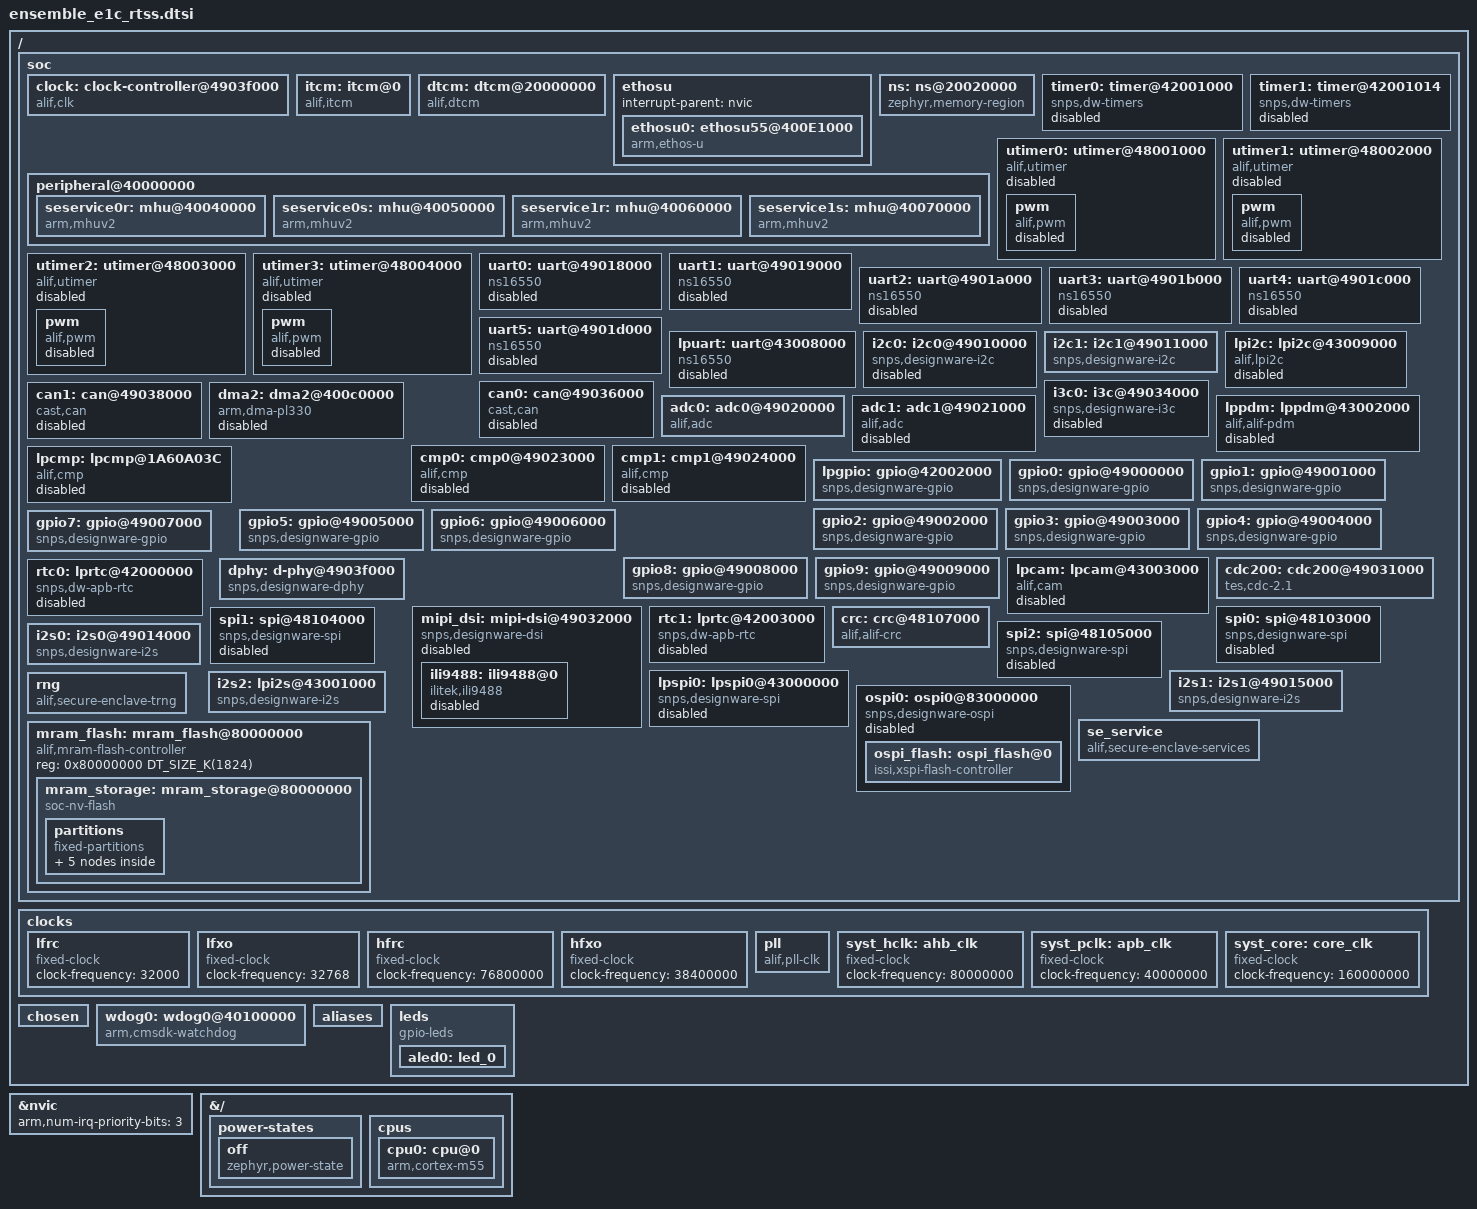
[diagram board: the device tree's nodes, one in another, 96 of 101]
/* Copyright (c) 2024 Alif Semiconductor
 *
 * SPDX-License-Identifier: Apache-2.0
 */
#include <arm/armv8.1-m.dtsi>
#include <zephyr/dt-bindings/timer/alif_utimer.h>
#include <zephyr/dt-bindings/pwm/pwm.h>
#include <zephyr/dt-bindings/clock/alif_balletto_clocks.h>
#include <zephyr/dt-bindings/mipi_dsi/mipi_dsi.h>
#include <zephyr/dt-bindings/display/ili9xxx.h>
#include <zephyr/dt-bindings/gpio/gpio.h>
#include <mem.h>
/ {
	soc {
		clock: clock-controller@4903f000 {
			compatible = "alif,clk";
			reg =  <0x4903F000 0xB0
				0x4902F000 0xBC
				0x1A604000 0x44
				0x1A609000 0x14
				0x43007000 0x2C>;
			reg-names = "master_clkctrl",
				     "slave_clkctrl",
				     "aon_clkctrl",
				     "vbat_clkctrl",
				     "m55he_clkctrl";
			#clock-cells = <1>;
			status = "okay";
		};
		itcm: itcm@0 {
			compatible = "alif,itcm", "zephyr,memory-region";
			reg = <0x0 DT_SIZE_K(512)>;
			itcm_global_base = <0x58000000>;
			zephyr,memory-region = "ITCM";
		};

		dtcm: dtcm@20000000 {
			compatible = "alif,dtcm", "zephyr,memory-region";
			dtcm_global_base = <0x58800000>;
			reg = <0x20000000 DT_SIZE_K(1536)>;
			zephyr,memory-region = "DTCM";
		};

		ethosu {
			#address-cells = <1>;
			#size-cells = <0>;
			interrupt-parent = <&nvic>;
			ethosu0: ethosu55@400E1000 {
				compatible = "arm,ethos-u";
				reg = <0x400E1000>;
				interrupts = <55 3>;
				secure-enable;
				privilege-enable;
				status = "okay";
			};
		};

		ns: ns@20020000 {
			compatible = "zephyr,memory-region", "mmio-region";
			reg = <0x20020000 DT_SIZE_K(512)>;
			zephyr,memory-region = "NS";
		};

		peripheral@40000000 {
			#address-cells = < 0x1 >;
			#size-cells = < 0x1 >;
			ranges = < 0x0 0x40000000 0x2000000 >;

			seservice0r: mhu@40040000 {
				compatible = "arm,mhuv2";
				reg = < 0x40040000 0x1000 >;
				interrupts = < 37 3 >;
				interrupt-names = "rx";
			};
			seservice0s: mhu@40050000 {
				compatible = "arm,mhuv2";
				reg = < 0x40050000 0x1000 >;
				interrupts = < 38 3 >;
				interrupt-names = "tx";
			};
			seservice1r: mhu@40060000 {
				compatible = "arm,mhuv2";
				reg = < 0x40060000 0x1000 >;
				interrupts = < 39 3 >;
				interrupt-names = "rx";
			};
			seservice1s: mhu@40070000 {
				compatible = "arm,mhuv2";
				reg = < 0x40070000 0x1000 >;
				interrupts = < 40 3 >;
				interrupt-names = "tx";
			};
		};

		timer0: timer@42001000 {
			compatible = "snps,dw-timers";
			reg = <0x42001000 0x14>;
			interrupts = < 60 3 >;
			clocks = <&clock ALIF_LPTIMER0_S32K_CLK>;
			status = "disabled";
		};

		timer1: timer@42001014 {
			compatible = "snps,dw-timers";
			reg = <0x42001014 0x14>;
			interrupts = < 61 3 >;
			clocks = <&clock ALIF_LPTIMER1_S32K_CLK>;
			status = "disabled";
		};

		utimer0: utimer@48001000 {
			compatible = "alif,utimer";
			reg = <0x48001000 0x1000 0x48000000 0x24>;
			reg-names = "timer", "global";
			timer-id = <0>;
			clock-frequency = <160000000>;
			counter-direction = < ALIF_UTIMER_COUNTER_DIRECTION_UP >;
			driver-enable = < ALIF_UTIMER_DRIVER_A_OUTPUT_ENABLE >;
			status = "disabled";

			pwm {
				compatible = "alif,pwm";
				#pwm-cells = <3>;
				status = "disabled";
			};
		};

		utimer1: utimer@48002000 {
			compatible = "alif,utimer";
			reg = <0x48002000 0x1000 0x48000000 0x24>;
			reg-names = "timer", "global";
			timer-id = <1>;
			clock-frequency = <160000000>;
			counter-direction = < ALIF_UTIMER_COUNTER_DIRECTION_UP >;
			driver-enable = < ALIF_UTIMER_DRIVER_A_OUTPUT_ENABLE >;
			status = "disabled";

			pwm {
				compatible = "alif,pwm";
				#pwm-cells = <3>;
				status = "disabled";
			};
		};

		utimer2: utimer@48003000 {
			compatible = "alif,utimer";
			reg = <0x48003000 0x1000 0x48000000 0x24>;
			reg-names = "timer", "global";
			timer-id = <2>;
			clock-frequency = <160000000>;
			counter-direction = < ALIF_UTIMER_COUNTER_DIRECTION_UP >;
			driver-enable = < ALIF_UTIMER_DRIVER_A_OUTPUT_ENABLE >;
			status = "disabled";

			pwm {
				compatible = "alif,pwm";
				#pwm-cells = <3>;
				status = "disabled";
			};
		};

		utimer3: utimer@48004000 {
			compatible = "alif,utimer";
			reg = <0x48004000 0x1000 0x48000000 0x24>;
			reg-names = "timer", "global";
			timer-id = <3>;
			clock-frequency = <160000000>;
			counter-direction = < ALIF_UTIMER_COUNTER_DIRECTION_UP >;
			driver-enable = < ALIF_UTIMER_DRIVER_A_OUTPUT_ENABLE >;
			status = "disabled";

			pwm {
				compatible = "alif,pwm";
				#pwm-cells = <3>;
				status = "disabled";
			};
		};

		uart0: uart@49018000 {
			compatible = "ns16550";
			reg = <0x49018000 0x100>;
			/* SYST_PCLK (APB bus) 40MHz baud clock */
			clock-frequency = <40000000>;
			interrupts = <124 3>;
			reg-shift = <2>;
			current-speed = <115200>;
			pinctrl-0 = < &pinctrl_uart0 >;
			pinctrl-names = "default";
			fifo-size = <32>;
			status = "disabled";
		};

		uart1: uart@49019000 {
			compatible = "ns16550";
			reg = <0x49019000 0x100>;
			/* SYST_PCLK (APB bus) 40MHz baud clock */
			clock-frequency = <40000000>;
			interrupts = <125 3>;
			reg-shift = <2>;
			current-speed = <115200>;
			pinctrl-0 = < &pinctrl_uart1 >;
			pinctrl-names = "default";
			fifo-size = <32>;
			status = "disabled";
		};

		uart2: uart@4901a000 {
			compatible = "ns16550";
			reg = <0x4901a000 0x100>;
			/* SYST_PCLK (APB bus) 40MHz baud clock */
			clock-frequency = <40000000>;
			interrupts = <126 3>;
			reg-shift = <2>;
			current-speed = <115200>;
			pinctrl-0 = < &pinctrl_uart2 >;
			pinctrl-names = "default";
			fifo-size = <32>;
			status = "disabled";
		};

		uart3: uart@4901b000 {
			compatible = "ns16550";
			reg = <0x4901b000 0x100>;
			/* SYST_PCLK (APB bus) 40MHz baud clock */
			clock-frequency = <40000000>;
			interrupts = <127 3>;
			reg-shift = <2>;
			current-speed = <115200>;
			pinctrl-0 = < &pinctrl_uart3 >;
			pinctrl-names = "default";
			fifo-size = <32>;
			status = "disabled";
		};

		uart4: uart@4901c000 {
			compatible = "ns16550";
			reg = <0x4901c000 0x100>;
			/* SYST_PCLK (APB bus) 40MHz baud clock */
			clock-frequency = <40000000>;
			interrupts = <128 3>;
			reg-shift = <2>;
			current-speed = <115200>;
			pinctrl-0 = < &pinctrl_uart4 >;
			pinctrl-names = "default";
			fifo-size = <32>;
			status = "disabled";
		};

		uart5: uart@4901d000 {
			compatible = "ns16550";
			reg = <0x4901d000 0x100>;
			/* SYST_PCLK (APB bus) 40MHz baud clock */
			clock-frequency = <40000000>;
			interrupts = <129 3>;
			reg-shift = <2>;
			current-speed = <115200>;
			pinctrl-0 = < &pinctrl_uart5 >;
			pinctrl-names = "default";
			fifo-size = <32>;
			status = "disabled";
		};

		lpuart: uart@43008000 {
			compatible = "ns16550";
			reg = <0x43008000 0x100>;
			/* RTSS_HE_CLK 160MHz baud clock */
			clock-frequency = <160000000>;
			interrupts = <45 3>;
			reg-shift = <2>;
			current-speed = <115200>;
			pinctrl-0 = < &pinctrl_lpuart >;
			pinctrl-names = "default";
			fifo-size = <32>;
			status = "disabled";
		};

		i2c0: i2c0@49010000 {
			compatible = "snps,designware-i2c";
			clock-frequency = <100000>;
			#address-cells = <1>;
			#size-cells = <0>;
			reg = <0x49010000 0x1000>;
			pinctrl-0 = < &pinctrl_i2c0 >;
			pinctrl-names = "default";
			interrupt-parent = <&nvic>;
			interrupts = <132 3>;
			status = "disabled";
		};

		i2c1: i2c1@49011000 {
			compatible = "snps,designware-i2c";
			clock-frequency = <100000>;
			#address-cells = <1>;
			#size-cells = <0>;
			reg = <0x49011000 0x1000>;
			pinctrl-0 = < &pinctrl_i2c1 >;
			pinctrl-names = "default";
			interrupt-parent = <&nvic>;
			interrupts = <133 3>;
			status = "okay";
		};

		lpi2c: lpi2c@43009000 {
			compatible = "alif,lpi2c";
			#address-cells = <1>;
			#size-cells = <0>;
			pinctrl-names = "default";
			pinctrl-0 = <&pinctrl_lpi2c>;
			reg = <0x43009000 0x100>;
			interrupts = <47 3>;
			status = "disabled";
		};

		i3c0: i3c@49034000 {
			compatible      = "snps,designware-i3c";
			#address-cells  = <3>;
			#size-cells     = <0>;
			reg             = <0x49034000 0x1000>;
			interrupt-parent= <&nvic>;
			interrupts      = <136 3>;
			clocks          = <&clock ALIF_I3C_CLK>;
			pinctrl-0       = <&pinctrl_i3c0>;
			pinctrl-names   = "default";
			i3c-scl-hz      = <12500000>;
			i2c-scl-hz      = <400000>;
			status          = "disabled";
		};

		can0: can@49036000 {
			#address-cells  = <1>;
			#size-cells     = <1>;
			compatible      = "cast,can";
			reg             = <0x49036000 0x1000 0x49037000 0x1000>;
			reg-names       = "can_reg", "can_cnt_reg";
			interrupt-parent= <&nvic>;
			interrupts      = <104 3>;
			interrupt-names = "can_interrupt";
			clocks          = <&clock ALIF_CANFD0_160M_CLK>;
			clk-speed       = <20000000>;
			pinctrl-0       = <&pinctrl_can0>;
			pinctrl-names   = "default";
			status          = "disabled";
		};

		can1: can@49038000 {
			#address-cells  = <1>;
			#size-cells     = <1>;
			compatible      = "cast,can";
			reg             = <0x49038000 0x1000 0x49039000 0x1000>;
			reg-names       = "can_reg", "can_cnt_reg";
			interrupt-parent= <&nvic>;
			interrupts      = <105 3>;
			interrupt-names = "can_interrupt";
			clocks          = <&clock ALIF_CANFD1_160M_CLK>;
			clk-speed       = <20000000>;
			pinctrl-0       = <&pinctrl_can1>;
			pinctrl-names   = "default";
			status          = "disabled";
		};

		dma2: dma2@400c0000 {
			compatible = "arm,dma-pl330";
			reg = <0x400C0000 0x1000>;
			reg-names = "pl330_regs";
			dma-channels = <4>;
			#dma-cells = <2>;
			interrupt-parent = <&nvic>;
			interrupts = <0 3>, <1 3>, <2 3>, <3 3>, <32 3>;
			interrupt-names = "channel0", "channel1",
					"channel2", "channel3",
					"abort";
			status = "disabled";
		};

		adc0: adc0@49020000{
			compatible = "alif,adc";
			reg =	<0x49020000 0x1000>,
				<0x49020000 0x100>,
				<0x49023000 0x100>,
				<0x1A604000 0x100>;
			reg-names = "adc_reg", "analog_reg", "comp_reg", "aon_regs";

			comparator_threshold_a = <0x01>;
			comparator_threshold_b = <0x01>;
			comparator_threshold_comparasion = "ABOVE_THRESHOLD_A_AND_B";

			sample-width		= <16>;
			clock_div		= <2>;
			avg_sample_num		= <256>;
			shift_n_bits		= <8>;
			shift_direction		= "RIGHT_SHIFT";
			comparator_en;
			comparator_bias		= "2.5_MS/s";
			driver_instance		= "ADC_INSTANCE_ADC12_0";
			adc_channel_scan	= "SINGLE_CHANNEL_SCAN";
			adc_conversion_mode	= "SINGLE_SHOT_CONVERSION";
			/* pga_enable; */     /* This property is valid in differential mode only */
			pga_gain		= "ADC_PGA_GAIN_0_DB";
			pinctrl-0		= < &pinctrl_adc0 >;
			pinctrl-names		= "default";
			interrupts		= <151 3>,
						  <154 3>,
						  <157 3>,
						  <160 3>;
			interrupt-names = "continuous_intr",
					  "single_shot_intr",
					  "comparator_a_intr",
					  "comparator_b_intr";
			status = "okay";
		};

		adc1: adc1@49021000{
			compatible = "alif,adc";
			reg =	<0x49021000 0x1000>,
				<0x49020000 0x100>,
				<0x49023000 0x100>,
				<0x1A604000 0x100>;
			reg-names = "adc_reg", "analog_reg", "comp_reg", "aon_regs";

			comparator_threshold_a = <0x01>;
			comparator_threshold_b = <0x01>;
			comparator_threshold_comparasion = "ABOVE_THRESHOLD_A_AND_B";

			sample-width		= <16>;
			clock_div		= <2>;
			avg_sample_num		= <256>;
			shift_n_bits		= <8>;
			shift_direction		= "RIGHT_SHIFT";
			comparator_en;
			comparator_bias		= "2.5_MS/s";
			driver_instance		= "ADC_INSTANCE_ADC12_1";
			adc_channel_scan	= "SINGLE_CHANNEL_SCAN";
			adc_conversion_mode	= "SINGLE_SHOT_CONVERSION";
			/* pga_enable; */     /* This property is valid in differential mode only */
			pga_gain		= "ADC_PGA_GAIN_0_DB";
			pinctrl-0		= < &pinctrl_adc1 >;
			pinctrl-names		= "default";
			interrupts		= <152 3>,
						  <155 3>,
						  <158 3>,
						  <161 3>;
			interrupt-names		= "continuous_intr",
						  "single_shot_intr",
						  "comparator_a_intr",
						  "comparator_b_intr";
			status = "disabled";
		};

		lppdm: lppdm@43002000 {
			compatible = "alif,alif-pdm";
			reg = <0x43002000 0x1000>;
			interrupts = <49 3>;
			pinctrl-0 = < &pinctrl_lppdm >;
			pinctrl-names = "default";
			fifo_watermark = <5>;
			bypass_iir_filter = <1>;
			status = "disabled";
		};

		cmp0: cmp0@49023000 {
			compatible = "alif,cmp";
			reg = <0x49023000 0x1000>,
			      <0x49023000 0x1000>;
			reg-names        = "cmp_reg", "config_reg";
			pinctrl-0        = < &pinctrl_cmp0 >;
			pinctrl-names    = "default";
			driver_instance  = "CMP_INSTANCE_0";
			positive_input   = "CMP_POS_IN0";
			negative_input   = "CMP_NEG_IN3";
			hysteresis_level = "42mV";
			interrupts       = <167 3>;
			cmp-gpios        = <&gpio4 3 GPIO_ACTIVE_HIGH>;
			status = "disabled";
		};

		cmp1: cmp1@49024000 {
			compatible = "alif,cmp";
			reg = <0x49024000 0x1000>,
				<0x49023000 0x1000>;
			reg-names	 = "cmp_reg", "config_reg";
			pinctrl-0	 = < &pinctrl_cmp1 >;
			pinctrl-names	 = "default";
			driver_instance	 = "CMP_INSTANCE_1";
			positive_input	 = "CMP_POS_IN0";
			negative_input	 = "CMP_NEG_IN3";
			hysteresis_level = "42mV";
			interrupts	 = <168 3>;
			cmp-gpios	 = <&gpio4 7 GPIO_ACTIVE_HIGH>;
			status = "disabled";
		};

		lpcmp: lpcmp@1A60A03C {
			compatible = "alif,cmp";
			reg = <0x1A60A03C 0x10>,
			  <0x1A60A03C 0x10>;
			reg-names = "cmp_reg", "config_reg";
			pinctrl-0	 = < &pinctrl_lpcmp >;
			pinctrl-names	 = "default";
			driver_instance	 = "CMP_INSTANCE_LP";
			positive_input	 = "CMP_POS_IN0";
			negative_input	 = "CMP_NEG_IN0";
			hysteresis_level = "42mV";
			interrupts	 = <56 3>;
			status = "disabled";
		};

		lpgpio: gpio@42002000 {
			compatible = "snps,designware-gpio";
			reg = <0x42002000 0x1000>;
			ngpios = <2>;
			interrupts = <171 3>, <172 3>;
			pinctrl-0 = < &pinctrl_lpgpio >;
			pinctrl-names = "default";
			gpio-controller;
			#gpio-cells = <2>;
		};
		gpio0: gpio@49000000 {
			compatible = "snps,designware-gpio";
			reg = <0x49000000 0x1000>;
			ngpios = <8>;
			interrupts =	<179 3>, <180 3>,
					<181 3>, <182 3>,
					<183 3>, <184 3>,
					<185 3>, <186 3>;
			/* Commenting this here as gpio0 is used for
			 * jtag connection
			 *
			 *	pinctrl-0 = < &pinctrl_gpio0 >;
			 *	pinctrl-names = "default";
			 */
			gpio-controller;
			#gpio-cells = <2>;
		};
		gpio1: gpio@49001000 {
			compatible = "snps,designware-gpio";
			reg = <0x49001000 0x1000>;
			ngpios = <8>;
			interrupts =	<187 3>, <188 3>,
					<189 3>, <190 3>,
					<191 3>, <192 3>,
					<193 3>, <194 3>;
			/* Commenting this here as gpio1 is used for
			 * jtag connection
			 *
			 *	pinctrl-0 = < &pinctrl_gpio1 >;
			 *	pinctrl-names = "default";
			 */
			gpio-controller;
			#gpio-cells = <2>;
		};
		gpio2: gpio@49002000 {
			compatible = "snps,designware-gpio";
			reg = <0x49002000 0x1000>;
			ngpios = <8>;
			interrupts =	<195 3>, <196 3>,
					<197 3>, <198 3>,
					<199 3>, <200 3>,
					<201 3>, <202 3>;
			pinctrl-0 = < &pinctrl_gpio2 >;
			pinctrl-names = "default";
			gpio-controller;
			#gpio-cells = <2>;
		};
		gpio3: gpio@49003000 {
			compatible = "snps,designware-gpio";
			reg = <0x49003000 0x1000>;
			ngpios = <8>;
			interrupts =	<203 3>, <204 3>,
					<205 3>, <206 3>,
					<207 3>, <208 3>,
					<209 3>, <210 3>;
			pinctrl-0 = < &pinctrl_gpio3 >;
			pinctrl-names = "default";
			gpio-controller;
			#gpio-cells = <2>;
		};
		gpio4: gpio@49004000 {
			compatible = "snps,designware-gpio";
			reg = <0x49004000 0x1000>;
			ngpios = <8>;
			interrupts =	<211 3>, <212 3>,
					<213 3>, <214 3>,
					<215 3>, <216 3>,
					<217 3>, <218 3>;
			pinctrl-0 = < &pinctrl_gpio4 >;
			pinctrl-names = "default";
			gpio-controller;
			#gpio-cells = <2>;
		};
		gpio5: gpio@49005000 {
			compatible = "snps,designware-gpio";
			reg = <0x49005000 0x1000>;
			ngpios = <8>;
			interrupts =	<219 3>, <220 3>,
					<221 3>, <222 3>,
					<223 3>, <224 3>,
					<225 3>, <226 3>;
			pinctrl-0 = < &pinctrl_gpio5 >;
			pinctrl-names = "default";
			gpio-controller;
			#gpio-cells = <2>;
		};
		gpio6: gpio@49006000 {
			compatible = "snps,designware-gpio";
			reg = <0x49006000 0x1000>;
			ngpios = <8>;
			interrupts =	<227 3>, <228 3>,
					<229 3>, <230 3>,
					<231 3>, <232 3>,
					<233 3>, <234 3>;
			pinctrl-0 = < &pinctrl_gpio6 >;
			pinctrl-names = "default";
			gpio-controller;
			#gpio-cells = <2>;
		};
		gpio7: gpio@49007000 {
			compatible = "snps,designware-gpio";
			reg = <0x49007000 0x1000>;
			ngpios = <8>;
			interrupts =	<235 3>, <236 3>,
					<237 3>, <238 3>,
					<239 3>, <240 3>,
					<241 3>, <242 3>;
			pinctrl-0 = < &pinctrl_gpio7 >;
			pinctrl-names = "default";
			gpio-controller;
			#gpio-cells = <2>;
		};
		gpio8: gpio@49008000 {
			compatible = "snps,designware-gpio";
			reg = <0x49008000 0x1000>;
			ngpios = <8>;
			interrupts =	<243 3>, <244 3>,
					<245 3>, <246 3>,
					<247 3>, <248 3>,
					<249 3>, <250 3>;
			pinctrl-0 = < &pinctrl_gpio8 >;
			pinctrl-names = "default";
			gpio-controller;
			#gpio-cells = <2>;
		};
		gpio9: gpio@49009000 {
			compatible = "snps,designware-gpio";
			reg = <0x49009000 0x1000>;
			ngpios = <3>;
			interrupts =	<251 3>, <252 3>,
					<253 3>;
			pinctrl-0 = < &pinctrl_gpio9 >;
			pinctrl-names = "default";
			gpio-controller;
			#gpio-cells = <2>;
		};

		lpcam: lpcam@43003000 {
			compatible = "alif,cam";
			reg = <0x43003000 0x1000>;
			interrupts = <54 3>;

			pinctrl-0 = < &pinctrl_lpcam >;
			pinctrl-names = "default";
			status = "disabled";
		};

		cdc200: cdc200@49031000 {
			compatible = "tes,cdc-2.1";
			reg = <0x49031000 0x1000>;
			status = "okay";
			interrupts =	<333 3>,
					<334 3>,
					<335 3>,
					<336 3>,
					<337 3>,
					<338 3>,
					<339 3>,
					<340 3>,
					<341 3>,
					<342 3>;
			interrupt-names = "scanline_0",
					  "scanline_1",
					  "fifo_warning_0",
					  "fifo_warning_1",
					  "fifo_underrun_0",
					  "fifo_underrun_1",
					  "bus_error_0",
					  "bus_error_1",
					  "reg_reload_0",
					  "reg_reload_1";
			pinctrl-0 = < &pinctrl_cdc200 >;
			pinctrl-names = "default";

			clocks = <&clock ALIF_DPI_CLK>, <&clock ALIF_CDC200_PIX_SYST_ACLK>;
			clock-names = "dpi-clk-en", "pixel-clk";
			/* Panel Config */
			width = <800>;
			height = <480>;
			hfront-porch = <210>;
			hback-porch = <46>;
			hsync-len = <1>;
			vfront-porch = <22>;
			vback-porch = <23>;
			vsync-len = <1>;
			hsync-active = <0>;
			vsync-active = <0>;
			de-active = <1>;
			pixelclk-active = <0>;
			clock-frequency = <2779910>;
			/* BG Layer color is 24-bit in size. */
			bg-color = <0x5a5a5a>;

			/* Layer 0 Config */
			enable-l1 = <1>;
			pixel-fmt-l1 = "rgb-565";
			/* Default color for Layer is 32-bit in size. */
			def-back-color-l1 = <0x00ff00>;
			win-x0-l1 = <0>;
			win-y0-l1 = <0>;
			win-x1-l1 = <300>;
			win-y1-l1 = <480>;
			blend-factor1-l1 = <4>;
			blend-factor2-l1 = <5>;
			const-alpha-l1 = <0x7f>;

			/* Layer 1 Config */
			enable-l2 = <1>;
			pixel-fmt-l2 = "argb-8888";
			win-x0-l2 = <500>;
			win-y0-l2 = <0>;
			win-x1-l2 = <800>;
			win-y1-l2 = <68>;
			blend-factor1-l2 = <4>;
			blend-factor2-l2 = <5>;
			const-alpha-l2 = <0xaf>;
		};

		dphy: d-phy@4903f000{
			compatible = "snps,designware-dphy";
			reg = <0x4903f000 0x40>,
			      <0x49032000 0x1000>,
			      <0x49033000 0x1000>;
			reg-names = "expmst_reg", "dsi_reg", "csi_reg";

			clocks = <&clock ALIF_MIPI_PLLREF_CLK>;
			clock-names = "pllref-clk";

			ref-frequency = <38400000>;
			cfg-clk-frequency = <25000000>;
			status = "okay";
		};

		mipi_dsi: mipi-dsi@49032000 {
			#address-cells = <1>;
			#size-cells = <0>;
			compatible = "snps,designware-dsi";
			reg = <0x49032000 0x1000>;
			interrupts = <343 3>;
			cdc-if = <&cdc200>;
			phy-if = <&dphy>;

			clocks = <&clock ALIF_DSI_CLK>, <&clock ALIF_CDC200_PIX_SYST_ACLK>,
				<&clock ALIF_MIPI_TXDPHY_CLK>;
			clock-names = "dsi-clk-en", "pixel-clk", "tx-dphy-clk";
			dpi-shutdn-active = <1>;
			dpi-colorm-active = <1>;
			vid-pkt-size = <320>;
			ecc-recv-en;
			crc-recv-en;
			frame-ack-en;
			panel-max-lane-bandwidth = <500000000>;
			//dpi-video-pattern-gen = "vertical-color-bar";
			status = "disabled";

			ili9488: ili9488@0 {
				compatible = "ilitek,ili9488";
				reg = <0>;
				pixel-format = <ILI9XXX_PIXEL_FORMAT_RGB666_PACKED>;
				width = <320>;
				height = <480>;
				rotation = <0>;

				display-inversion;

				vmctrl = [00 25 80 25];
				pwctrl1 = [0f 0c];
				pwctrl2 = [41];
				pgamctrl = [00 10 14 01 0e 04 33 56 48 03 0c 0b 2b 34 0f];
				ngamctrl = [00 12 18 05 12 06 40 34 57 06 10 0c 3b 3f 0f];
				data-lanes = <1>;
				reset-gpios = <&gpio8 0 GPIO_ACTIVE_LOW>;
				bl-gpios = <&gpio8 1 GPIO_ACTIVE_HIGH>;
				status = "disabled";
			};
		};
		rtc0: lprtc@42000000 {
			compatible = "snps,dw-apb-rtc";
			reg = <0x42000000 0x1000>;
			interrupts = <58 3>;
			clock-frequency = <32768>;
			prescaler = <0>;
			load-value = <0>;
			status = "disabled";
		};
		rtc1: lprtc@42003000 {
			compatible = "snps,dw-apb-rtc";
			reg = <0x42003000 0x1000>;
			interrupts = <59 3>;
			clock-frequency = <32768>;
			prescaler = <0>;
			load-value = <0>;
			status = "disabled";
		};

		crc: crc@48107000 {
			compatible = "alif,alif-crc";
			reg = <0x48107000 0x1000>;
			crc_algo = "CRC_8_BIT_SIZE";
			status = "okay";
		};

		spi0: spi@48103000 {
			dwc-ssi;
			compatible = "snps,designware-spi";
			#address-cells = <1>;
			#size-cells = <0>;
			pinctrl-0 = < &pinctrl_spi0 >;
			pinctrl-names = "default";
			reg = <0x48103000 0x1000>;
			interrupt-parent = <&nvic>;
			interrupts = <137 3>;
			cs-gpios = <&gpio5 3 0>;
			clocks = <&syst_hclk>;
			fifo-depth = <16>;
			max-xfer-size = <32>;
			status = "disabled";
		};
		spi1: spi@48104000 {
			dwc-ssi;
			compatible = "snps,designware-spi";
			#address-cells = <1>;
			#size-cells = <0>;
			pinctrl-0 = < &pinctrl_spi1 >;
			pinctrl-names = "default";
			reg = <0x48104000 0x1000>;
			interrupt-parent = <&nvic>;
			interrupts = <138 3>;
			cs-gpios = <&gpio8 7 0>;
			clocks = <&syst_hclk>;
			fifo-depth = <16>;
			max-xfer-size = <32>;
			status = "disabled";
		};
		spi2: spi@48105000 {
			dwc-ssi;
			compatible = "snps,designware-spi";
			#address-cells = <1>;
			#size-cells = <0>;
			pinctrl-0 = < &pinctrl_spi2 >;
			pinctrl-names = "default";
			reg = <0x48105000 0x1000>;
			interrupt-parent = <&nvic>;
			interrupts = <139 3>;
			cs-gpios = <&gpio4 5 0>;
			clocks = <&syst_hclk>;
			fifo-depth = <16>;
			max-xfer-size = <32>;
			status = "disabled";
		};
		lpspi0: lpspi0@43000000 {
			compatible = "snps,designware-spi";
			#address-cells = <1>;
			#size-cells = <0>;
			pinctrl-0 = < &pinctrl_lpspi0 >;
			pinctrl-names = "default";
			reg = <0x43000000 0x1000>;
			interrupt-parent = <&nvic>;
			interrupts = <46 3>;
			cs-gpios = <&gpio2 0 0>;
			clocks = <&syst_core>;
			fifo-depth = <16>;
			max-xfer-size = <32>;
			status = "disabled";
		};
		i2s0: i2s0@49014000 {
			compatible = "snps,designware-i2s";
			clock-frequency = <76800000>;
			driver_instance	= "I2S_INSTANCE_0";
			reg = <0x49014000 0x1000>;
			pinctrl-names = "default";
			pinctrl-0 = <&pinctrl_i2s0>;
			interrupts = <141 3>;
		};
		i2s1: i2s1@49015000 {
			compatible = "snps,designware-i2s";
			clock-frequency = <76800000>;
			driver_instance	= "I2S_INSTANCE_1";
			reg = <0x49015000 0x1000>;
			pinctrl-names = "default";
			pinctrl-0 = <&pinctrl_i2s1>;
			interrupts = <142 3>;
		};
		i2s2: lpi2s@43001000 {
			compatible = "snps,designware-i2s";
			clock-frequency = <76800000>;
			driver_instance	= "I2S_INSTANCE_4";
			reg = <0x43001000 0x1000>;
			pinctrl-names = "default";
			pinctrl-0 = <&pinctrl_lpi2s>;
			interrupts = <48 3>;
		};
		ospi0: ospi0@83000000 {
			compatible = "snps,designware-ospi";
			#address-cells = <1>;
			#size-cells = <0>;
			reg = <0x83000000 0x1000>;
			pinctrl-0 = <&pinctrl_ospi0>;
			pinctrl-names = "default";
			interrupt-parent = <&nvic>;
			interrupts = <96 3>;
			aes-reg = <0x83001000 0x100>;
			bus-speed = <10000000>;
			cs-pin = <0>;
			ddr-drive-edge;
			rx-ds-delay = <11>;
			tx-fifo-threshold = <64>;
			status = "disabled";

			ospi_flash: ospi_flash@0 {
				compatible = "issi,xspi-flash-controller";
				reg = <0x0>;
				erase-value = <0xff>;
				num-of-sector = <8192>;
				page-size = <256>;
				sector-size = <4096>;
				write-block-size = <2>;
			};
		};
		rng: rng {
			compatible = "alif,secure-enclave-trng";
			status = "okay";
		};
		se_service: se_service {
			compatible = "alif,secure-enclave-services";
			mhuv2-send-node = <&seservice0s>;
			mhuv2-recv-node = <&seservice0r>;
			status = "okay";
		};
		mram_flash: mram_flash@80000000 {
			compatible = "alif,mram-flash-controller";
			/* Usable MRAM size for applications is 1824 KB */
			reg = <0x80000000 DT_SIZE_K(1824)>;

			#address-cells = <1>;
			#size-cells = <1>;
			mram_storage: mram_storage@80000000 {
				compatible = "soc-nv-flash";
				reg = <0x80000000 DT_SIZE_K(1824)>;
				erase-block-size = <1024>;
				write-block-size = <16>;
			};
		};
	};
	clocks {
		lfrc: lfrc {
			compatible = "fixed-clock";
			clock-frequency = <32000>;
			status = "okay";
			#clock-cells = <0>;
		};
		lfxo: lfxo {
			compatible = "fixed-clock";
			clock-frequency = <32768>;
			status = "okay";
			#clock-cells = <0>;
		};
		hfrc: hfrc {
			compatible = "fixed-clock";
			clock-frequency = <76800000>;
			status = "okay";
			#clock-cells = <0>;
		};
		hfxo: hfxo {
			compatible = "fixed-clock";
			clock-frequency = <38400000>;
			status = "okay";
			#clock-cells = <0>;
		};
		pll: pll {
			compatible = "alif,pll-clk";
			pll_clk1-frequency = <160000000>;
			pll_clk2-frequency = <120000000>;
			pll_clk3-frequency = <480000000>;
			status = "okay";
		};
		syst_hclk: ahb_clk {
			compatible = "fixed-clock";
			clock-frequency = <80000000>;
			#clock-cells = <0>;
		};
		syst_pclk: apb_clk {
			compatible = "fixed-clock";
			clock-frequency = <40000000>;
			#clock-cells = <0>;
		};
		syst_core: core_clk {
			compatible = "fixed-clock";
			clock-frequency = <160000000>;
			#clock-cells = <0>;
		};
	};
	chosen {
		zephyr,flash-controller = &mram_flash;
		zephyr,flash = &mram_storage;
		zephyr,code-partition = &slot0_partition;
		zephyr,sram = &dtcm;
		zephyr,dtcm = &dtcm;
		zephyr,entropy = &rng;
		zephyr,display = &cdc200;
	};
	wdog0: wdog0@40100000{
		compatible = "arm,cmsdk-watchdog";
		reg = <0x40100000 0x1000>;
		clocks = <&syst_core>;
		status = "okay";
	};
	aliases {
		led0 = &aled0;
		watchdog0 = &wdog0;
		mipi-dsi = &mipi_dsi;
		panel = &ili9488;
	};
	leds {
		compatible = "gpio-leds";
		aled0: led_0 {
			gpios = <&gpio4 5 0>;
			label = "LED0_G";
		};
	};
};

&mram_storage {
	partitions {
		compatible = "fixed-partitions";
		#address-cells = <1>;
		#size-cells = <1>;

		boot_partition: partition@0 {
			label = "mcuboot";
			reg = <0x00000000 DT_SIZE_K(64)>;
			read-only;
		};

		slot0_partition: partition@10000 {
			label = "image-0";
			reg = <0x00010000 DT_SIZE_K(843)>;
		};

		slot1_partition: partition@E2C00 {
			label = "image-1";
			reg = <0x000E2C00 DT_SIZE_K(843)>;
		};

		scratch_partition: partition@1B5800 {
			label = "image-scratch";
			reg = <0x001B5800 DT_SIZE_K(64)>;
		};

		storage_partition: partition@1C5800 {
			label = "storage";
			reg = <0x001C5800 DT_SIZE_K(10)>;
		};
	};
};

&nvic {
	arm,num-irq-priority-bits = <3>;
};

&{/} {
	power-states {
		off: off {
			compatible = "zephyr,power-state";
			power-state-name = "soft-off";
			min-residency-us = < 300000000 >;
		};
	};
	cpus {
		#address-cells = <1>;
		#size-cells = <0>;
		cpu0: cpu@0 {
			device_type = "cpu";
			compatible = "arm,cortex-m55";
			d-cache-line-size = <32>;
			i-cache-line-size = <32>;
			reg = <0>;
			cpu-power-states = <&off>;
		};
	};
};
